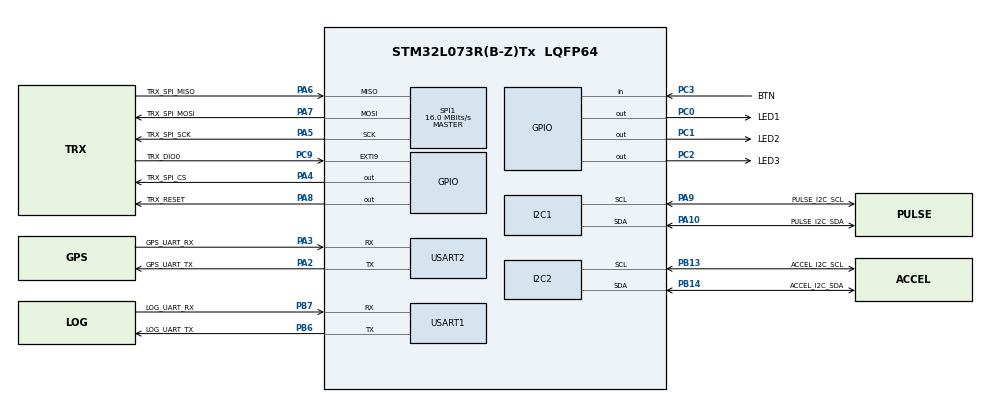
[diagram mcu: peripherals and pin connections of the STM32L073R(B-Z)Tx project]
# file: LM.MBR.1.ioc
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ADC.SamplingTime=ADC_SAMPLETIME_79CYCLES_5
I2C1.Timing=0x00B07CB4
I2C2.Timing=0x00B07CB4
Mcu.Family=STM32L0
Mcu.Name=STM32L073R(B-Z)Tx
Mcu.Package=LQFP64
NVIC.EXTI4_15_IRQn=true\:0\:0\:false\:false\:true\:true\:true\:true
NVIC.RTC_IRQn=true\:0\:0\:false\:false\:true\:true\:true\:true
PA10.GPIO_Label=PULSE_I2C_SDA
PA10.Mode=I2C
PA10.Signal=I2C1_SDA
PA13.GPIO_Label=SWDIO
PA13.Mode=Serial_Wire
PA13.Signal=SYS_SWDIO
PA14.GPIO_Label=SWCLK
PA14.Mode=Serial_Wire
PA14.Signal=SYS_SWCLK
PA2.GPIO_Label=GPS_UART_TX
PA2.Mode=Asynchronous
PA2.Signal=USART2_TX
PA3.GPIO_Label=GPS_UART_RX
PA3.Mode=Asynchronous
PA3.Signal=USART2_RX
PA4.GPIO_Label=TRX_SPI_CS
PA4.PinState=GPIO_PIN_SET
PA4.Signal=GPIO_Output
PA5.GPIO_Label=TRX_SPI_SCK
PA5.Mode=Full_Duplex_Master
PA5.Signal=SPI1_SCK
PA6.GPIO_Label=TRX_SPI_MISO
PA6.Mode=Full_Duplex_Master
PA6.Signal=SPI1_MISO
PA7.GPIO_Label=TRX_SPI_MOSI
PA7.Mode=Full_Duplex_Master
PA7.Signal=SPI1_MOSI
PA8.GPIO_Label=TRX_RESET
PA8.PinState=GPIO_PIN_RESET
PA8.Signal=GPIO_Output
PA9.GPIO_Label=PULSE_I2C_SCL
PA9.Mode=I2C
PA9.Signal=I2C1_SCL
PB13.GPIO_Label=ACCEL_I2C_SCL
PB13.Mode=I2C
PB13.Signal=I2C2_SCL
PB14.GPIO_Label=ACCEL_I2C_SDA
PB14.Mode=I2C
PB14.Signal=I2C2_SDA
PB6.GPIO_Label=LOG_UART_TX
PB6.Mode=Asynchronous
PB6.Signal=USART1_TX
PB7.GPIO_Label=LOG_UART_RX
PB7.Mode=Asynchronous
PB7.Signal=USART1_RX
PC0.GPIO_Label=LED1
PC0.PinState=GPIO_PIN_RESET
PC0.Signal=GPIO_Output
PC1.GPIO_Label=LED2
PC1.PinState=GPIO_PIN_RESET
PC1.Signal=GPIO_Output
PC2.GPIO_Label=LED3
PC2.PinState=GPIO_PIN_RESET
PC2.Signal=GPIO_Output
PC3.GPIO_Label=BTN
PC3.Signal=GPIO_Input
PC9.GPIO_Label=TRX_DIO0
PC9.Signal=GPXTI9
ProjectManager.HeapSize=0x64
ProjectManager.StackSize=0x200
ProjectManager.TargetToolchain=STM32CubeIDE
RCC.AHBFreq_Value=32000000
RCC.APB1Freq_Value=32000000
RCC.APB1TimFreq_Value=32000000
RCC.APB2Freq_Value=32000000
RCC.APB2TimFreq_Value=32000000
RCC.HCLKFreq_Value=32000000
RCC.HSE_VALUE=8000000
RCC.HSI16_VALUE=16000000
RCC.HSI48_VALUE=48000000
RCC.HSI_VALUE=16000000
RCC.LSE_VALUE=32768
RCC.MSI_VALUE=2097000
RCC.PLLMUL=RCC_PLLMUL_4
RCC.SYSCLKFreq_VALUE=32000000
RCC.SYSCLKSource=RCC_SYSCLKSOURCE_PLLCLK
RCC.VCOOutputFreq_Value=64000000
RTC.WakeUpClock-WakeUp=RTC_WAKEUPCLOCK_RTCCLK_DIV2
RTC.WakeUpCounter-WakeUp=1200
SPI1.CalculateBaudRate=16.0 MBits/s
SPI1.Direction=SPI_DIRECTION_2LINES
SPI1.Mode=SPI_MODE_MASTER
SPI1.VirtualType=VM_MASTER
USART1.VirtualMode-Asynchronous=VM_ASYNC
USART2.VirtualMode-Asynchronous=VM_ASYNC
VP_ADC_TempSens_Input.Mode=IN-TempSens
VP_ADC_Vref_Input.Mode=IN-Vrefint
VP_RTC_VS_RTC_Activate.Mode=RTC_Enabled
VP_RTC_VS_RTC_WakeUp_intern.Mode=WakeUp
board=custom

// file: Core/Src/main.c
/* USER CODE BEGIN Header */
/**
  ******************************************************************************
  * @file           : main.c
  * @brief          : Main program body
  ******************************************************************************
  * @attention
  *
  * Copyright (c) 2025 STMicroelectronics.
  * All rights reserved.
  *
  * This software is licensed under terms that can be found in the LICENSE file
  * in the root directory of this software component.
  * If no LICENSE file comes with this software, it is provided AS-IS.
  *
  ******************************************************************************
  */
/* USER CODE END Header */
#include "main.h"
#include "adc.h"
#include "i2c.h"
#include "rtc.h"
#include "spi.h"
#include "usart.h"
#include "gpio.h"

/* USER CODE BEGIN Includes */
#include "project.h"

/* USER CODE END Includes */

void SystemClock_Config(void);

int main(void)
{

  /* MCU Configuration--------------------------------------------------------*/

  /* Reset of all peripherals, Initializes the Flash interface and the Systick. */
  HAL_Init();

  /* Configure the system clock */
  SystemClock_Config();

  /* Initialize all configured peripherals */
  MX_GPIO_Init();
  MX_I2C1_Init();
  MX_I2C2_Init();
  MX_SPI1_Init();
  MX_USART1_UART_Init();
  MX_USART2_UART_Init();
  MX_RTC_Init();
  MX_ADC_Init();
  /* USER CODE BEGIN 2 */
  project_main();
  /* USER CODE END 2 */

  /* Infinite loop */
  while (1)
  {

  }
}

void SystemClock_Config(void)
{
  LL_FLASH_SetLatency(LL_FLASH_LATENCY_1);
  while(LL_FLASH_GetLatency()!= LL_FLASH_LATENCY_1)
  {
  }
  LL_PWR_SetRegulVoltageScaling(LL_PWR_REGU_VOLTAGE_SCALE1);
  while (LL_PWR_IsActiveFlag_VOS() != 0)
  {
  }
  LL_RCC_HSI_Enable();

   /* Wait till HSI is ready */
  while(LL_RCC_HSI_IsReady() != 1)
  {

  }
  LL_RCC_HSI_SetCalibTrimming(16);
  LL_RCC_LSI_Enable();

   /* Wait till LSI is ready */
  while(LL_RCC_LSI_IsReady() != 1)
  {

  }
  LL_PWR_EnableBkUpAccess();
  if(LL_RCC_GetRTCClockSource() != LL_RCC_RTC_CLKSOURCE_LSI)
  {
    LL_RCC_ForceBackupDomainReset();
    LL_RCC_ReleaseBackupDomainReset();
    LL_RCC_SetRTCClockSource(LL_RCC_RTC_CLKSOURCE_LSI);
  }
  LL_RCC_EnableRTC();
  LL_RCC_PLL_ConfigDomain_SYS(LL_RCC_PLLSOURCE_HSI, LL_RCC_PLL_MUL_4, LL_RCC_PLL_DIV_2);
  LL_RCC_PLL_Enable();

   /* Wait till PLL is ready */
  while(LL_RCC_PLL_IsReady() != 1)
  {

  }
  LL_RCC_SetAHBPrescaler(LL_RCC_SYSCLK_DIV_1);
  LL_RCC_SetAPB1Prescaler(LL_RCC_APB1_DIV_1);
  LL_RCC_SetAPB2Prescaler(LL_RCC_APB2_DIV_1);
  LL_RCC_SetSysClkSource(LL_RCC_SYS_CLKSOURCE_PLL);

   /* Wait till System clock is ready */
  while(LL_RCC_GetSysClkSource() != LL_RCC_SYS_CLKSOURCE_STATUS_PLL)
  {

  }
  LL_SetSystemCoreClock(32000000);

   /* Update the time base */
  if (HAL_InitTick (TICK_INT_PRIORITY) != HAL_OK)
  {
    Error_Handler();
  }
  LL_RCC_SetUSARTClockSource(LL_RCC_USART1_CLKSOURCE_PCLK2);
  LL_RCC_SetUSARTClockSource(LL_RCC_USART2_CLKSOURCE_PCLK1);
  LL_RCC_SetI2CClockSource(LL_RCC_I2C1_CLKSOURCE_PCLK1);
}

void Error_Handler(void)
{
  __disable_irq();
  while (1)
  {
  }
}
